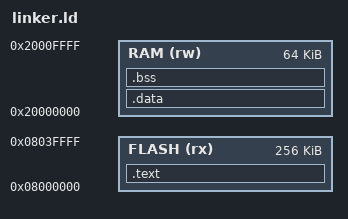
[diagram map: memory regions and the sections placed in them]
ENTRY(Reset_Handler)

MEMORY
{
  FLASH (rx) : ORIGIN = 0x08000000, LENGTH = 256K
  RAM   (rw) : ORIGIN = 0x20000000, LENGTH = 64K
}

SECTIONS
{
  .text :
  {
    *(.text*)
    *(.rodata*)
    _etext = .;
  } > FLASH

  .data : AT (_etext)
  {
    _sdata = .;
    *(.data*)
    _edata = .;
  } > RAM

  .bss :
  {
    _sbss = .;
    *(.bss*)
    *(COMMON)
    _ebss = .;
  } > RAM
}
